# MSP430FR5739 register map
File version: 1.1
CPU: msp430
Registers are 16-bit, access not given, reset 0x0 unless marked. A register's access mark holds for its fields unless they carry their own. Offsets are from the block's base; [hi:lo] are bit positions; {n}, {i} and the like mark numbered series.

## RTC_B__Real_Time_Clock
Base 0x00000000
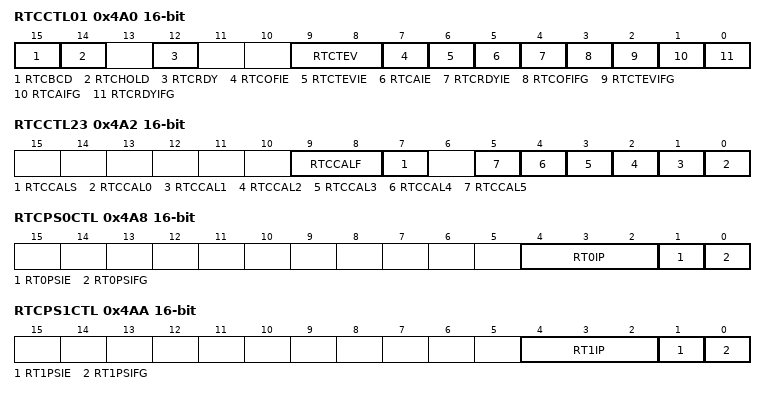
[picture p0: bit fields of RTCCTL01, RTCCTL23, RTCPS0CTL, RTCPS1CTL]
0x4A0 RTCCTL01 — Real Timer Control 0/1
  [15] RTCBCD — [15:15] RTC BCD 0:Binary / 1:BCD
  [14] RTCHOLD — [14:14] RTC Hold
  [12] RTCRDY — [12:12] RTC Ready
  [9:8] RTCTEV — [9:8] RTC Time Event 1
    0=RTC Time Event: 0 (Min. changed); 1=RTC Time Event: 1 (Hour changed); 2=RTC Time Event: 2 (12:00 changed); 3=RTC Time Event: 3 (00:00 changed)
  [7] RTCOFIE — [7:7] RTC 32kHz cyrstal oscillator fault interrupt enable
  [6] RTCTEVIE — [6:6] RTC Time Event Interrupt Enable Flag
  [5] RTCAIE — [5:5] RTC Alarm Interrupt Enable Flag
  [4] RTCRDYIE — [4:4] RTC Ready Interrupt Enable Flag
  [3] RTCOFIFG — [3:3] RTC 32kHz cyrstal oscillator fault interrupt flag
  [2] RTCTEVIFG — [2:2] RTC Time Event Interrupt Flag
  [1] RTCAIFG — [1:1] RTC Alarm Interrupt Flag
  [0] RTCRDYIFG — [0:0] RTC Ready Interrupt Flag
0x4A2 RTCCTL23 — Real Timer Control 2/3
  [9:8] RTCCALF — [9:8] RTC Calibration Frequency Bit 1
    0=RTC Calibration Frequency: No Output; 1=RTC Calibration Frequency: 512 Hz; 2=RTC Calibration Frequency: 256 Hz; 3=RTC Calibration Frequency: 1 Hz
  [7] RTCCALS — [7:7] RTC Calibration Sign
  [n] RTCCAL{n} (n=0..5) — [{n}:{n}] RTC Calibration Bit {n}
0x4A8 RTCPS0CTL — Real Timer Prescale Timer 0 Control
  [4:2] RT0IP — [4:2] RTC Prescale Timer 0 Interrupt Interval Bit: 2
    0=RTC Prescale Timer 0 Interrupt Interval /2; 1=RTC Prescale Timer 0 Interrupt Interval /4; 2=RTC Prescale Timer 0 Interrupt Interval /8; 3=RTC Prescale Timer 0 Interrupt Interval /16; 4=RTC Prescale Timer 0 Interrupt Interval /32; 5=RTC Prescale Timer 0 Interrupt Interval /64; 6=RTC Prescale Timer 0 Interrupt Interval /128; 7=RTC Prescale Timer 0 Interrupt Interval /256
  [1] RT0PSIE — [1:1] RTC Prescale Timer 0 Interrupt Enable Flag
  [0] RT0PSIFG — [0:0] RTC Prescale Timer 0 Interrupt Flag
0x4AA RTCPS1CTL — Real Timer Prescale Timer 1 Control
  [4:2] RT1IP — [4:2] RTC Prescale Timer 1 Interrupt Interval Bit: 2
    0=RTC Prescale Timer 1 Interrupt Interval /2; 1=RTC Prescale Timer 1 Interrupt Interval /4; 2=RTC Prescale Timer 1 Interrupt Interval /8; 3=RTC Prescale Timer 1 Interrupt Interval /16; 4=RTC Prescale Timer 1 Interrupt Interval /32; 5=RTC Prescale Timer 1 Interrupt Interval /64; 6=RTC Prescale Timer 1 Interrupt Interval /128; 7=RTC Prescale Timer 1 Interrupt Interval /256
  [1] RT1PSIE — [1:1] RTC Prescale Timer 1 Interrupt Enable Flag
  [0] RT1PSIFG — [0:0] RTC Prescale Timer 1 Interrupt Flag
0x4AC RTCPS — Real Timer Prescale Timer Control
0x4AE RTCIV — Real Time Clock Interrupt Vector
0x4B0 RTCTIM0 — Real Time Clock Time 0
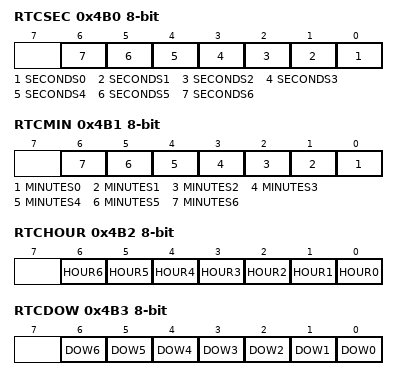
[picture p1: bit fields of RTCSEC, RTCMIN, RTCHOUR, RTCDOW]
0x4B0 RTCSEC 8-bit — Real Time Clock Seconds
  [n] SECONDS{n} (n=0..6) — [{n}:{n}] Real Time Clock Seconds Bit: {n}
0x4B1 RTCMIN 8-bit — Real Time Clock Minutes
  [n] MINUTES{n} (n=0..6) — [{n}:{n}] Real Time Clock Minutes Bit: {n}
0x4B2 RTCTIM1 — Real Time Clock Time 1
0x4B2 RTCHOUR 8-bit — Real Time Clock Hour
  [n] HOUR{n} (n=0..6) — [{n}:{n}] Real Time Clock Hour Bit: {n}
0x4B3 RTCDOW 8-bit — Real Time Clock Day of week
  [n] DOW{n} (n=0..6) — [{n}:{n}] Real Time Clock DOW Bit: {n}
0x4B4 RTCDATE — Real Time Clock Date
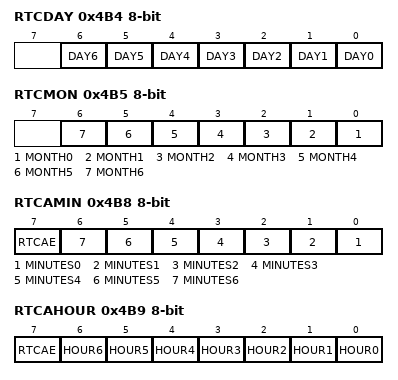
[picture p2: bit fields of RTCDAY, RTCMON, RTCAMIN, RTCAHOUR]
0x4B4 RTCDAY 8-bit — Real Time Clock Day
  [n] DAY{n} (n=0..6) — [{n}:{n}] Real Time Clock Day Bit: {n}
0x4B5 RTCMON 8-bit — Real Time Clock Month
  [n] MONTH{n} (n=0..6) — [{n}:{n}] Real Time Clock Month Bit: {n}
0x4B6 RTCYEAR — Real Time Clock Year
0x4B8 RTCAMINHR — Real Time Clock Alarm Min/Hour
0x4B8 RTCAMIN 8-bit — Real Time Clock Alarm Min
  [7] RTCAE — [7:7] Real Time Clock Alarm enable
  [n] MINUTES{n} (n=0..6) — [{n}:{n}] Real Time Clock Minutes Bit: {n}
0x4B9 RTCAHOUR 8-bit — Real Time Clock Alarm Hour
  [7] RTCAE — [7:7] Real Time Clock Alarm enable
  [n] HOUR{n} (n=0..6) — [{n}:{n}] Real Time Clock Hour Bit: {n}
0x4BA RTCADOWDAY — Real Time Clock Alarm day of week/day
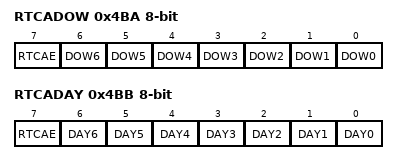
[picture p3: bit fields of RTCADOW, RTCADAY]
0x4BA RTCADOW 8-bit — Real Time Clock Alarm Day of week
  [7] RTCAE — [7:7] Real Time Clock Alarm enable
  [n] DOW{n} (n=0..6) — [{n}:{n}] Real Time Clock DOW Bit: {n}
0x4BB RTCADAY 8-bit — Real Time Clock Alarm Day
  [7] RTCAE — [7:7] Real Time Clock Alarm enable
  [n] DAY{n} (n=0..6) — [{n}:{n}] Real Time Clock Day Bit: {n}
0x4BC BIN2BCD — Real Time Binary-to-BCD conversion register
0x4BE BCD2BIN — Real Time BCD-to-binary conversion register
